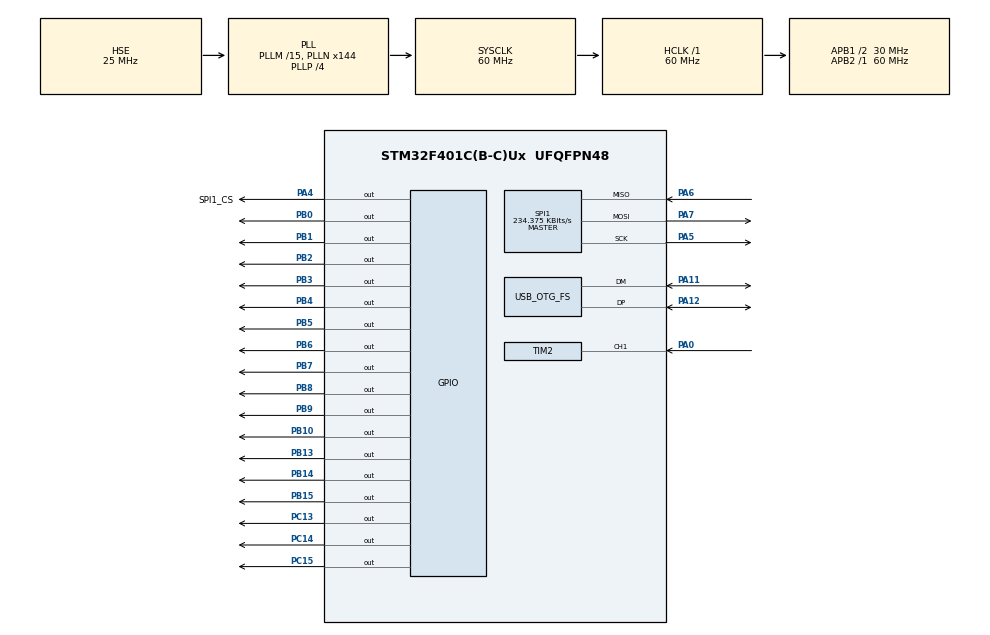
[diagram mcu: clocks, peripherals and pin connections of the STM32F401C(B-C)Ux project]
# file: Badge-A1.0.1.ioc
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Mcu.Family=STM32F4
PC13-ANTI_TAMP.GPIO_Speed=GPIO_SPEED_FREQ_LOW
PB10.PinState=GPIO_PIN_SET
PA6.Mode=Full_Duplex_Master
USB_DEVICE.CLASS_NAME_FS=MSC
RCC.CortexFreq_Value=60000000
TIM2.Channel-Input_Capture1_from_TI1=TIM_CHANNEL_1
FATFS._USE_LFN=2
PB10.GPIO_Speed=GPIO_SPEED_FREQ_VERY_HIGH
SPI1.VirtualType=VM_MASTER
PB10.GPIO_PuPd=GPIO_PULLUP
PB2.GPIO_Speed=GPIO_SPEED_FREQ_VERY_HIGH
PA11.Mode=Device_Only
PB13.Signal=GPIO_Output
PB15.Signal=GPIO_Output
PB3.GPIO_Speed=GPIO_SPEED_FREQ_VERY_HIGH
RCC.SYSCLKSource=RCC_SYSCLKSOURCE_PLLCLK
ProjectManager.StackSize=0x400
PA12.Signal=USB_OTG_FS_DP
PH0\ -\ OSC_IN.Signal=RCC_OSC_IN
SPI1.Direction=SPI_DIRECTION_2LINES
PB1.GPIO_PuPd=GPIO_PULLUP
RCC.HCLKFreq_Value=60000000
RCC.APB2TimFreq_Value=60000000
PB6.Signal=GPIO_Output
VP_TIM10_VS_ClockSourceINT.Mode=Enable_Timer
SPI1.CalculateBaudRate=234.375 KBits/s
RCC.AHBFreq_Value=60000000
RCC.HSE_VALUE=25000000
PA0-WKUP.GPIO_Speed=GPIO_SPEED_FREQ_VERY_HIGH
PA4.GPIO_PuPd=GPIO_PULLUP
PB2.Signal=GPIO_Output
PC13-ANTI_TAMP.Signal=GPIO_Output
PA4.GPIO_Speed=GPIO_SPEED_FREQ_VERY_HIGH
PB3.GPIO_PuPd=GPIO_PULLUP
PB1.GPIO_Speed=GPIO_SPEED_FREQ_VERY_HIGH
PA14.Mode=Serial_Wire
NVIC.TIM2_IRQn=true\:1\:0\:true\:false\:true\:true\:true
PB7.Signal=GPIO_Output
PB2.GPIO_PuPd=GPIO_PULLUP
Mcu.Package=UFQFPN48
PB9.Signal=GPIO_Output
TIM2.Prescaler=59
PB1.Signal=GPIO_Output
PA6.Signal=SPI1_MISO
NVIC.OTG_FS_IRQn=true\:1\:0\:true\:false\:true\:false\:true
PB9.GPIO_PuPd=GPIO_PULLUP
USB_OTG_FS.VirtualMode=Device_Only
PB5.GPIO_Speed=GPIO_SPEED_FREQ_VERY_HIGH
PB9.GPIO_Speed=GPIO_SPEED_FREQ_VERY_HIGH
RCC.APB1TimFreq_Value=60000000
VP_USB_DEVICE_VS_USB_DEVICE_MSC_FS.Mode=MSC_FS
SPI1.BaudRatePrescaler=SPI_BAUDRATEPRESCALER_256
USB_DEVICE.MSC_MEDIA_PACKET=4096
PA4.GPIO_Label=SPI1_CS
FATFS._MIN_SS=4096
PB4.Signal=GPIO_Output
PA5.Mode=Full_Duplex_Master
PB7.GPIO_Speed=GPIO_SPEED_FREQ_VERY_HIGH
PB7.GPIO_PuPd=GPIO_PULLUP
TIM10.Prescaler=59
PA7.Mode=Full_Duplex_Master
PC13-ANTI_TAMP.GPIO_PuPd=GPIO_PULLUP
USB_DEVICE.VirtualModeFS=Msc_FS
PB6.GPIO_PuPd=GPIO_PULLUP
PH1\ -\ OSC_OUT.Mode=HSE-External-Oscillator
PB8.GPIO_PuPd=GPIO_PULLUP
RCC.APB1CLKDivider=RCC_HCLK_DIV2
PC14-OSC32_IN.Signal=GPIO_Output
PA0-WKUP.Signal=S_TIM2_CH1_ETR
PB0.GPIO_Speed=GPIO_SPEED_FREQ_VERY_HIGH
PA13.Signal=SYS_JTMS-SWDIO
PH0\ -\ OSC_IN.Mode=HSE-External-Oscillator
ProjectManager.TargetToolchain=STM32CubeIDE
FATFS._CODE_PAGE=850
TIM2.ICFilter_CH1=0x03
PB4.GPIO_PuPd=GPIO_PULLUP
RCC.LSE_VALUE=32768
PC15-OSC32_OUT.Signal=GPIO_Output
VP_FATFS_VS_Generic.Mode=User_defined
PB10.Signal=GPIO_Output
PB14.Signal=GPIO_Output
PA5.Signal=SPI1_SCK
PH1\ -\ OSC_OUT.Signal=RCC_OSC_OUT
board=custom
RCC.VCOOutputFreq_Value=240000000
TIM10.Period=50
PB4.GPIO_Speed=GPIO_SPEED_FREQ_VERY_HIGH
RCC.APB2Freq_Value=60000000
SPI1.Mode=SPI_MODE_MASTER
PC15-OSC32_OUT.GPIO_PuPd=GPIO_PULLUP
TIM2.Period=10000
PA13.Mode=Serial_Wire
Mcu.Name=STM32F401C(B-C)Ux
FATFS._MAX_SS=4096
RCC.48MHZClocksFreq_Value=48000000
PB3.Signal=GPIO_Output
PA4.Signal=GPIO_Output
RCC.SYSCLKFreq_VALUE=60000000
PB5.Signal=GPIO_Output
PA12.Mode=Device_Only
PB5.GPIO_PuPd=GPIO_PULLUP
PA11.Signal=USB_OTG_FS_DM
SH.S_TIM2_CH1_ETR.0=TIM2_CH1,Input_Capture1_from_TI1
PA14.Signal=SYS_JTCK-SWCLK
ProjectManager.HeapSize=0x2000
NVIC.TIM1_UP_TIM10_IRQn=true\:0\:0\:false\:false\:true\:true\:true
RCC.HSI_VALUE=16000000
RCC.PLLP=RCC_PLLP_DIV4
RCC.PLLQ=5
NVIC.PriorityGroup=NVIC_PRIORITYGROUP_4
RCC.PLLM=15
RCC.PLLN=144
PB8.Signal=GPIO_Output
PA0-WKUP.GPIO_PuPd=GPIO_PULLUP
PC14-OSC32_IN.GPIO_PuPd=GPIO_PULLUP
PB6.GPIO_Speed=GPIO_SPEED_FREQ_VERY_HIGH
RCC.APB1Freq_Value=30000000
PB8.GPIO_Speed=GPIO_SPEED_FREQ_VERY_HIGH
PB0.Signal=GPIO_Output
USB_DEVICE.VirtualMode=Msc
PB0.GPIO_PuPd=GPIO_PULLUP
PA7.Signal=SPI1_MOSI

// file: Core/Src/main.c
/* USER CODE BEGIN Header */
/**
  ******************************************************************************
  * @file           : main.c
  * @brief          : Main program body
  ******************************************************************************
  * @attention
  *
  * <h2><center>&copy; Copyright (c) 2020 STMicroelectronics.
  * All rights reserved.</center></h2>
  *
  * This software component is licensed by ST under BSD 3-Clause license,
  * the "License"; You may not use this file except in compliance with the
  * License. You may obtain a copy of the License at:
  *                        opensource.org/licenses/BSD-3-Clause
  *
  ******************************************************************************
  */
/* USER CODE END Header */
#include "main.h"
#include "fatfs.h"
#include "spi.h"
#include "tim.h"
#include "usb_device.h"
#include "gpio.h"

/* USER CODE BEGIN Includes */
#include "Badge.h"
/* USER CODE END Includes */

void SystemClock_Config(void);

int main(void)
{

  /* MCU Configuration--------------------------------------------------------*/

  /* Reset of all peripherals, Initializes the Flash interface and the Systick. */
  HAL_Init();

  /* Configure the system clock */
  SystemClock_Config();

  /* Initialize all configured peripherals */
  MX_GPIO_Init();
  MX_SPI1_Init();
  MX_USB_DEVICE_Init();
  MX_FATFS_Init();
  MX_TIM2_Init();
  MX_TIM10_Init();
  /* USER CODE BEGIN 2 */
  //SPI_FLASH_Init();
  setup();
  /* USER CODE END 2 */

  /* Infinite loop */
  while (1)
  {

    /* USER CODE BEGIN 3 */
	loop();
  }
  /* USER CODE END 3 */
}

void SystemClock_Config(void)
{
  RCC_OscInitTypeDef RCC_OscInitStruct = {0};
  RCC_ClkInitTypeDef RCC_ClkInitStruct = {0};

  /** Configure the main internal regulator output voltage
  */
  __HAL_RCC_PWR_CLK_ENABLE();
  __HAL_PWR_VOLTAGESCALING_CONFIG(PWR_REGULATOR_VOLTAGE_SCALE2);
  /** Initializes the RCC Oscillators according to the specified parameters
  * in the RCC_OscInitTypeDef structure.
  */
  RCC_OscInitStruct.OscillatorType = RCC_OSCILLATORTYPE_HSE;
  RCC_OscInitStruct.HSEState = RCC_HSE_ON;
  RCC_OscInitStruct.PLL.PLLState = RCC_PLL_ON;
  RCC_OscInitStruct.PLL.PLLSource = RCC_PLLSOURCE_HSE;
  RCC_OscInitStruct.PLL.PLLM = 15;
  RCC_OscInitStruct.PLL.PLLN = 144;
  RCC_OscInitStruct.PLL.PLLP = RCC_PLLP_DIV4;
  RCC_OscInitStruct.PLL.PLLQ = 5;
  if (HAL_RCC_OscConfig(&RCC_OscInitStruct) != HAL_OK)
  {
    Error_Handler();
  }
  /** Initializes the CPU, AHB and APB buses clocks
  */
  RCC_ClkInitStruct.ClockType = RCC_CLOCKTYPE_HCLK|RCC_CLOCKTYPE_SYSCLK
                              |RCC_CLOCKTYPE_PCLK1|RCC_CLOCKTYPE_PCLK2;
  RCC_ClkInitStruct.SYSCLKSource = RCC_SYSCLKSOURCE_PLLCLK;
  RCC_ClkInitStruct.AHBCLKDivider = RCC_SYSCLK_DIV1;
  RCC_ClkInitStruct.APB1CLKDivider = RCC_HCLK_DIV2;
  RCC_ClkInitStruct.APB2CLKDivider = RCC_HCLK_DIV1;

  if (HAL_RCC_ClockConfig(&RCC_ClkInitStruct, FLASH_LATENCY_1) != HAL_OK)
  {
    Error_Handler();
  }
}

void Error_Handler(void)
{
  __disable_irq();
  while (1)
  {
  }
}

/************************ (C) COPYRIGHT STMicroelectronics *****END OF FILE****/
